# ESP32-S31 register map
Vendor: ESPRESSIF SYSTEMS (SHANGHAI) CO., LTD.; Series: ESP32 S-Series; File version: 1
CPU: RV32IMAFC r0p0, little endian, no MPU, FPU, 0 interrupt priority bits
Address unit: 32 bits
Registers are 32-bit, read-write, reset 0x0 unless marked. A register's access mark holds for its fields unless they carry their own. Offsets are from the block's base; [hi:lo] are bit positions; {n}, {i} and the like mark numbered series.

## CORDIC — CORDIC Peripheral
Base 0x2039B000
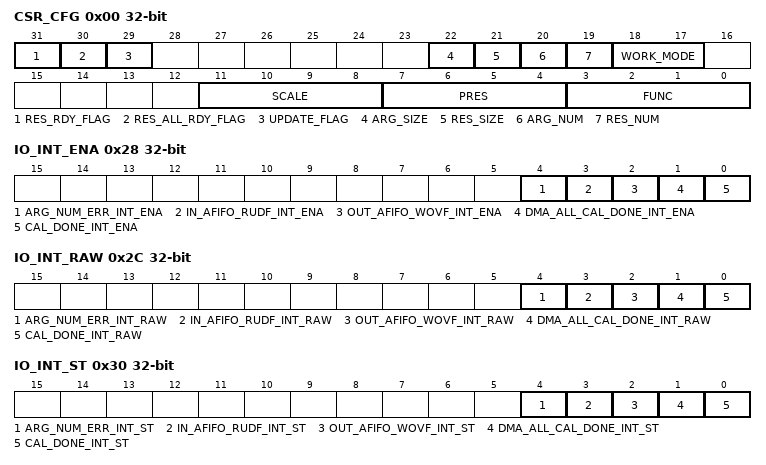
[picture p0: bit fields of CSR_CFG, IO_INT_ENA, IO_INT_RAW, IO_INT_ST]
0x00 CSR_CFG access per field — Cordic model config register
  [31] RES_RDY_FLAG ro — Used to indicate whether the operation result has been stored in the result register
  [30] RES_ALL_RDY_FLAG ro — Used to indicate whether the operation all result has been stored in the result register
  [29] UPDATE_FLAG rw — Used to synchronize register data to the computing core and start calculate
  [22] ARG_SIZE rw — Argument Size, 0: q1.15, 1: q1.31
  [21] RES_SIZE rw — Result Size, 0: q1.15, 1: q1.31
  [20] ARG_NUM rw — Argument number
  [19] RES_NUM rw — Result number
  [18:17] WORK_MODE rw — Select Cordic Module data transfer Mode,2'd0: reg_in,reg_out, no zero mode, 2'd1: dma_in, reg_out, no zero mode, 2'd2: dma_loop, 2'd3: reg_in, reg_out, zero mode
  [11:8] SCALE rw — The scaling of Input argument
  [7:4] PRES rw — Instruct the cordic calculate cycle number
  [3:0] FUNC rw — Used to inicate the type of operation currently being performed
0x04 ARG1 — Cordic argument 1 config register
  [31:0] DATA — First argument data for calculate
0x08 ARG2 — Cordic argument 2 config register
  [31:0] DATA — Second argument data for calculate
0x0C RES1 ro — Cordic result 1 receive register
  [31:0] DATA — First result data from calculate
0x10 RES2 ro — Cordic result 2 receive register
  [31:0] DATA — Second result data from calculate
0x28 IO_INT_ENA — Cordic interrupt enable singal configuration register.
  [4] ARG_NUM_ERR_INT_ENA — Write 1 to enable ARG_NUM_ERR_INT.
  [3] IN_AFIFO_RUDF_INT_ENA — Write 1 to enable IN_AFIFO_RUDF_INT.
  [2] OUT_AFIFO_WOVF_INT_ENA — Write 1 to enable OUT_AFIFO_WOVF_INT.
  [1] DMA_ALL_CAL_DONE_INT_ENA — Write 1 to enable DMA_ALL_CAL_DONE_INT.
  [0] CAL_DONE_INT_ENA — Write 1 to enable CAL_DONE_INT.
0x2C IO_INT_RAW ro — Cordic interrupt raw singal status register.
  [4] ARG_NUM_ERR_INT_RAW — The raw interrupt status of ARG_NUM_ERR_INT.
  [3] IN_AFIFO_RUDF_INT_RAW — The raw interrupt status of IN_AFIFO_RUDF_INT.
  [2] OUT_AFIFO_WOVF_INT_RAW — The raw interrupt status of OUT_AFIFO_WOVF_INT.
  [1] DMA_ALL_CAL_DONE_INT_RAW — The raw interrupt status of DMA_ALL_CAL_DONE_INT.
  [0] CAL_DONE_INT_RAW — The raw interrupt status of CAL_DONE_INT.
0x30 IO_INT_ST ro — Cordic interrupt singal status register.
  [4] ARG_NUM_ERR_INT_ST — The masked interrupt status of ARG_NUM_ERR_INT.
  [3] IN_AFIFO_RUDF_INT_ST — The masked interrupt status of IN_AFIFO_RUDF_INT.
  [2] OUT_AFIFO_WOVF_INT_ST — The masked interrupt status of OUT_AFIFO_WOVF_INT.
  [1] DMA_ALL_CAL_DONE_INT_ST — The masked interrupt status of DMA_ALL_CAL_DONE_INT.
  [0] CAL_DONE_INT_ST — The masked interrupt status of CAL_DONE_INT.
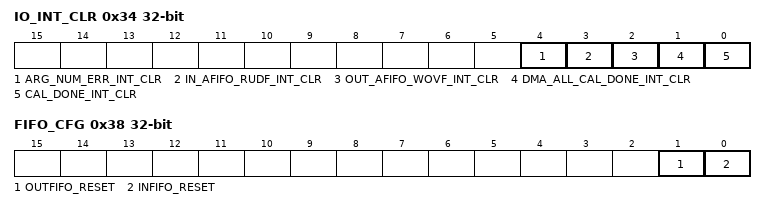
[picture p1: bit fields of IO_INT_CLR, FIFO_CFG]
0x34 IO_INT_CLR wo — Cordic interrupt clear singal configuration register.
  [4] ARG_NUM_ERR_INT_CLR — Write 1 to clear ARG_NUM_ERR_INT.
  [3] IN_AFIFO_RUDF_INT_CLR — Write 1 to clear IN_AFIFO_RUDF_INT.
  [2] OUT_AFIFO_WOVF_INT_CLR — Write 1 to clear OUT_AFIFO_WOVF_INT.
  [1] DMA_ALL_CAL_DONE_INT_CLR — Write 1 to clear DMA_ALL_CAL_DONE_INT.
  [0] CAL_DONE_INT_CLR — Write 1 to clear CAL_DONE_INT.
0x38 FIFO_CFG wo — Cordic FIFO configuration register.
  [1] OUTFIFO_RESET, [0] INFIFO_RESET
0x3C CLK — Cordic clk configuration register.
  [31] EN — Force clock on for this register file
0x40 VERSION reset 0x2411250
  [27:0] DATE — Version of this register file

## DS — Digital Signature
Base 0x2050C000
{0x0+i} Y_MEM[{i}] (i=0..511) 8-bit access not given — memory that stores Y
{0x200+i} M_MEM[{i}] (i=0..511) 8-bit access not given — memory that stores M
{0x400+i} RB_MEM[{i}] (i=0..511) 8-bit access not given — memory that stores Rb
{0x600+i} BOX_MEM[{i}] (i=0..47) 8-bit access not given — memory that stores BOX
{0x630+i} IV_MEM[{i}] (i=0..15) 8-bit access not given — memory that stores IV
{0x800+i} X_MEM[{i}] (i=0..511) 8-bit access not given — memory that stores X
{0xA00+i} Z_MEM[{i}] (i=0..511) 8-bit access not given — memory that stores Z
0xE00 SET_START wo — Activates the DS module
  [0] SET_START — Configures whether or not to activate the DS peripheral.\\ 0: Invalid\\ 1: Activate the DS peripheral\\
0xE04 SET_CONTINUE wo — DS continue control register
  [0] SET_CONTINUE — set this bit to continue DS operation.
0xE08 SET_FINISH wo — Ends DS operation
  [0] SET_FINISH — Configures whether or not to end DS operation. \\ 0: Invalid\\ 1: End DS operation\\
0xE0C QUERY_BUSY ro — Status of the DS module
  [0] QUERY_BUSY — Represents whether or not the DS module is idle.\\ 0: The DS module is idle\\ 1: The DS module is busy\\
0xE10 QUERY_KEY_WRONG ro — Checks the reason why \begin{math}DS_KEY\end{math} is not ready
  [3:0] QUERY_KEY_WRONG — Represents the specific problem with HMAC initialization.\\ 0: HMAC is not called\\ 1-15: HMAC was activated, but the DS peripheral did not successfully receive the \begin{math}DS_KEY\end{math} from the HMAC peripheral. (The biggest value is 15)\\
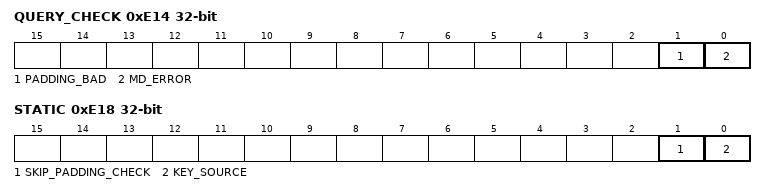
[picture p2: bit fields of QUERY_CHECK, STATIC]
0xE14 QUERY_CHECK ro — Queries DS check result
  [1] PADDING_BAD — Represents whether or not the padding check passes.\\ 0: The padding check passes\\ 1: The padding check fails\\
  [0] MD_ERROR — Represents whether or not the MD check passes.\\ 0: The MD check passes\\ 1: The MD check fails\\
0xE18 STATIC — DS configure key source register
  [1] SKIP_PADDING_CHECK — digital signature padding check bypass bit. \\ 1'b0: padding check enabled.\\ 1'b1: padding check skipped. \\
  [0] KEY_SOURCE — digital signature key source bit. \\ 1'b0: key is from hmac.\\ 1'b1: key is from key manager. \\
0xE20 DATE reset 0x20250819 — DS version control register
  [29:0] DATE — ds version information
0xE24 TIMEOUT_LIMIT reset 0xFFFFFFFF — DS timeout limit configurate register
  [31:0] TIMEOUT_LIMIT — The timeout limitation for waiting sub-IP.
